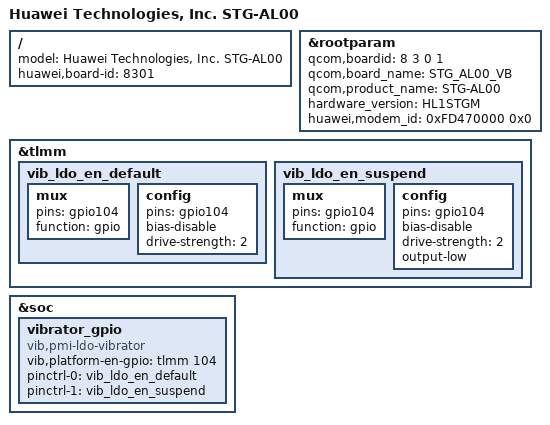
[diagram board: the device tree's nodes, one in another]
/dts-v1/;
/plugin/;

#include "../common/common.dtsi"
#include "huawei-wifi.dtsi"
#include "huawei-nfc.dtsi"
#include "huawei-charger.dtsi"
/ {
    model = "Huawei Technologies, Inc. STG-AL00";
    huawei,board-id = <8301>;
};

&rootparam {
    /* auto_key_info @ name: boardid type: uint32 default: 0 */
    qcom,boardid = <8 3 0 1>;
    qcom,board_name = "STG_AL00_VB";
    qcom,product_name = "STG-AL00";
    hardware_version = "HL1STGM";
    huawei,modem_id = <0xFD470000 0x0>;
};

&tlmm {
	vib_ldo_en_default:vib_ldo_en_default {
		mux {
			pins = "gpio104";
			function = "gpio";
		};
		config {
			pins = "gpio104";
			bias-disable;
			drive-strength = <2>;
		};
	};
	vib_ldo_en_suspend:vib_ldo_en_suspend {
		mux {
			pins = "gpio104";
			function = "gpio";
		};
		config {
			pins = "gpio104";
			bias-disable;
			drive-strength = <2>;
			output-low;
		};
	};
};

&soc {
	vibrator_gpio {
		compatible = "vib,pmi-ldo-vibrator";
		vib,platform-en-gpio = <&tlmm 104 GPIO_ACTIVE_HIGH>;
		pinctrl-names = "default","suspend";
		pinctrl-0 = <&vib_ldo_en_default>;
		pinctrl-1 = <&vib_ldo_en_suspend>;
	};
};
